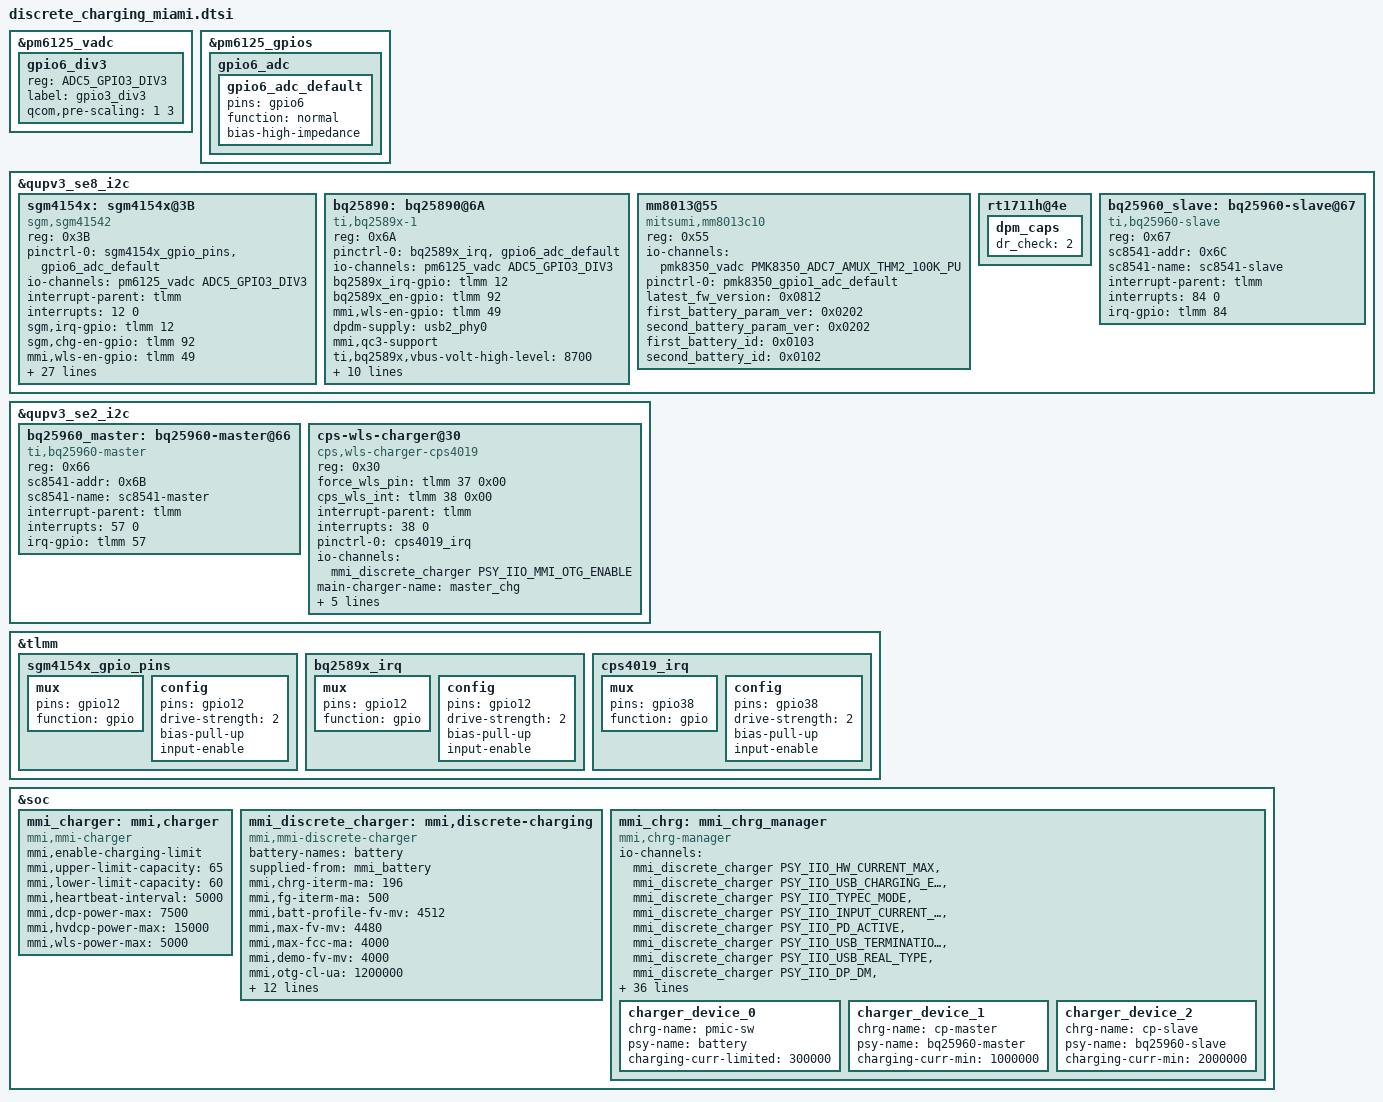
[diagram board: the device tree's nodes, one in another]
/* Copyright (c) 2021, The Linux Foundation. All rights reserved.
 *
 * This program is free software; you can redistribute it and/or modify
 * it under the terms of the GNU General Public License version 2 and
 * only version 2 as published by the Free Software Foundation.
 *
 * This program is distributed in the hope that it will be useful,
 * but WITHOUT ANY WARRANTY; without even the implied warranty of
 * MERCHANTABILITY or FITNESS FOR A PARTICULAR PURPOSE.  See the
 * GNU General Public License for more details.
 */

#include <dt-bindings/iio/qti_power_supply_iio.h>

&pm6125_vadc {
	gpio6_div3{
		reg = <ADC5_GPIO3_DIV3>;
		label = "gpio3_div3";
		qcom,pre-scaling = <1 3>;
	};
};

&pm6125_gpios {
	gpio6_adc{
		gpio6_adc_default:gpio6_adc_default{
			pins = "gpio6";
			function = "normal";
			bias-high-impedance;
		};
	};
};

&qupv3_se8_i2c {
	status = "okay";

	sgm4154x: sgm4154x@3B {
		status = "okay";
		compatible = "sgm,sgm41542";
		reg = <0x3B>;

		pinctrl-names = "default";
		pinctrl-0 = <&sgm4154x_gpio_pins &gpio6_adc_default>;
		#io-channel-cells = <1>;
		io-channels = <&pm6125_vadc ADC5_GPIO3_DIV3>;
		io-channel-names = "gpio3_div3";

		interrupt-parent = <&tlmm>;
		interrupts = <12 0>;            //irq num base on hardware design
		sgm,irq-gpio = <&tlmm 12 0>;     //irq num base on hardware design
		sgm,chg-en-gpio = <&tlmm 92 0>;   //gpio num base on hardware design  1.MTK parent node name is pio  2.QUALCOMM parent node name is tlmm or other
		mmi,wls-en-gpio = <&tlmm 49 0>;

		dpdm-supply = <&usb2_phy0>;
		mmi,qc3-support;
		mmi,wls-max-icl = <1000000>;
		input-voltage-limit-microvolt = <4700000>;

		/* sw jeita  parameter customer defined*/
		enable_sw_jeita;
		jeita_temp_above_t4_cv = <0>;
		jeita_temp_t3_to_t4_cv = <4100000>;
		jeita_temp_t2_to_t3_cv = <4350000>;
		jeita_temp_t1_to_t2_cv = <4350000>;
		jeita_temp_t0_to_t1_cv = <0>;
		jeita_temp_below_t0_cv = <0>;

		jeita_temp_above_t4_cc_current = <0>;
		jeita_temp_t3_to_t4_cc_current = <1000000>;
		jeita_temp_t2_to_t3_cc_current = <1250000>;
		jeita_temp_t1_to_t2_cc_current = <1000000>;
		jeita_temp_below_t0_cc_current = <0>;

		temp_t4_thres = <50>;
		temp_t4_thres_minus_x_degree = <48>;
		temp_t3_thres = <45>;
		temp_t3_thres_minus_x_degree = <45>;
		temp_t2_thres = <20>;
		temp_t2_thres_plus_x_degree = <15>;
		temp_t1_thres = <0>;
		temp_t1_thres_plus_x_degree = <0>;
		temp_t0_thres = <0>;
		temp_t0_thres_plus_x_degree = <2>;
		temp_neg_10_thres = <0>;
	};

	bq25890: bq25890@6A {
		status = "okay";
		compatible = "ti,bq2589x-1";
		reg = <0x6A>;

		pinctrl-names = "default";
		pinctrl-0 = <&bq2589x_irq &gpio6_adc_default>;
		#io-channel-cells = <1>;
		io-channels = <&pm6125_vadc ADC5_GPIO3_DIV3>;
		io-channel-names = "gpio3_div3";

		bq2589x_irq-gpio = <&tlmm 12 0>;
		bq2589x_en-gpio = <&tlmm 92 0>;
		mmi,wls-en-gpio = <&tlmm 49 0>;
		dpdm-supply = <&usb2_phy0>;

		mmi,qc3-support;
		ti,bq2589x,vbus-volt-high-level = <8700>;/* tune adapter to output 9v */
		ti,bq2589x,vbus-volt-low-level = <4400>;/* tune adapter to output 5v */
		ti,bq2589x,vbat-min-volt-to-tuneup = <3000>;
		ti,bq2589x,charge-voltage = <4450>;
		ti,bq2589x,charge-current = <3000>;
		ti,bq2589x,term-current = <128>;
		ti,bq2589x,enable-auto-dpdm;
		ti,bq2589x,enable-termination;
		ti,bq2589x,enable-ico;
		ti,bq2589x,use-absolute-vindpm;
		ti,bq2589x,vindpm = <4700>;
	};

	mm8013@55 {
		compatible = "mitsumi,mm8013c10";
		reg = <0x55>;
		status = "okay";
		io-channels = <&pmk8350_vadc PMK8350_ADC7_AMUX_THM2_100K_PU>;
		io-channel-names = "batt_therm";

		pinctrl-names = "default";
		pinctrl-0 = <&pmk8350_gpio1_adc_default>;

		latest_fw_version = <0x0812>;
		first_battery_param_ver = <0x0202>;
		second_battery_param_ver = <0x0202>;

		first_battery_id = <0x0103>;
		second_battery_id = <0x0102>;
	};

	rt1711h@4e {
		dpm_caps {
			/* 0: disable, 1: prefer_ufp, 2: prefer_dfp */
			dr_check = <2>;
		};
	};

};

&qupv3_se2_i2c {
	status = "okay";
	bq25960_master:bq25960-master@66 {
		status = "okay";
		compatible = "ti,bq25960-master";
		reg = <0x66>;
		sc8541-addr = <0x6B>;
		sc8541-name = "sc8541-master";
		#io-channel-cells = <1>;
		interrupt-parent = <&tlmm>;
		interrupts = <57 0>;
		irq-gpio = <&tlmm 57 0>;
	};

};

&qupv3_se8_i2c {
	status = "okay";
	bq25960_slave:bq25960-slave@67 {
		status = "okay";
		compatible = "ti,bq25960-slave";
		reg = <0x67>;
		sc8541-addr = <0x6C>;
		sc8541-name = "sc8541-slave";
		#io-channel-cells = <1>;
		interrupt-parent = <&tlmm>;
		interrupts = <84 0>;
		irq-gpio = <&tlmm 84 0>;
	};

};

&qupv3_se2_i2c {
	status = "okay";
	cps-wls-charger@30 {
		status = "okay";
		compatible = "cps,wls-charger-cps4019";
		reg = <0x30>;
		force_wls_pin = <&tlmm 37 0x00>;
		cps_wls_int = <&tlmm 38 0x00>;
		interrupt-parent = <&tlmm>;
		interrupts = <38 0>;
		interrupt-names = "cps_wls_int";

		pinctrl-names = "default";
		pinctrl-0 = <&cps4019_irq>;

		io-channels = <&mmi_discrete_charger PSY_IIO_MMI_OTG_ENABLE>;
		io-channel-names = "otg_enable";

		main-charger-name = "master_chg";
		supplied-from = "battery";

		wireless-fw-name = "cps4019.hex";
		fw_ver_major = <0>;
		fw_ver_minor = <0xE>;

		use_bl_in_h;
	};
};

&tlmm {
	sgm4154x_gpio_pins: sgm4154x_gpio_pins {
		mux {
			pins = "gpio12";
			function = "gpio";
		};

		config {
			pins = "gpio12";
			drive-strength = <2>;
			bias-pull-up;
			input-enable;
		};
	};
	bq2589x_irq: bq2589x_irq {
		mux {
			pins = "gpio12";
			function = "gpio";
		};

		config {
			pins = "gpio12";
			drive-strength = <2>;
			bias-pull-up;
			input-enable;
		};
	};

	cps4019_irq: cps4019_irq {
		mux {
			pins = "gpio38";
			function = "gpio";
		};

		config {
			pins = "gpio38";
			drive-strength = <2>;
			bias-pull-up;
			input-enable;
		};
	};
};

&soc {
	mmi_charger: mmi,charger {
		status = "ok";
		compatible = "mmi,mmi-charger";
		mmi,enable-charging-limit;
		mmi,upper-limit-capacity = <65>;
		mmi,lower-limit-capacity = <60>;
		mmi,heartbeat-interval = <5000>;
		mmi,dcp-power-max = <7500>;
		mmi,hvdcp-power-max = <15000>;
		mmi,wls-power-max = <5000>;
	};

	mmi_discrete_charger: mmi,discrete-charging {
		status = "ok";
		compatible = "mmi,mmi-discrete-charger";
		#io-channel-cells = <1>;
		battery-names = "battery";
		supplied-from = "mmi_battery";

		mmi,chrg-iterm-ma = <196>;
		mmi,fg-iterm-ma = <500>;
		mmi,batt-profile-fv-mv = <4512>;
		mmi,max-fv-mv = <4480>;
		mmi,max-fcc-ma = <4000>;
		mmi,demo-fv-mv = <4000>;
		mmi,otg-cl-ua = <1200000>;
		mmi,wls-max-icl-ua = <1000000>;
		mmi,df-serialnum = "SB18D50729";
		mmi,mmi-temp-zones = <0 4200 800 0>,
				<10 4250 2000 1000>,
				<15 0 2000 2000>,
				<45 0 4000 4000>,
				<60 4200 4000 0>;
		mmi,mmi-ffc-zones =
				<15 4480 196 500>,
				<25 4512 590 500>,
				<35 4512 712 500>,
				<45 4512 804 500>,
				<60 4480 196 500>;
		mmi,thermal-mitigation = <4000000 3000000 2500000
				2000000 1500000
				1200000 900000
				600000 300000>;
		mmi,usb-pd-supported;
		mmi,cfg-chgmod-to-fg;
	};

	mmi_chrg: mmi_chrg_manager {
		compatible = "mmi,chrg-manager";
		#io-channel-cells = <1>;
		io-channels = <&mmi_discrete_charger PSY_IIO_HW_CURRENT_MAX>,
				<&mmi_discrete_charger PSY_IIO_USB_CHARGING_ENABLED>,
				<&mmi_discrete_charger PSY_IIO_TYPEC_MODE>,
				<&mmi_discrete_charger PSY_IIO_INPUT_CURRENT_SETTLED>,
				<&mmi_discrete_charger PSY_IIO_PD_ACTIVE>,
				<&mmi_discrete_charger PSY_IIO_USB_TERMINATION_ENABLED>,
				<&mmi_discrete_charger PSY_IIO_USB_REAL_TYPE>,
				<&mmi_discrete_charger PSY_IIO_DP_DM>,
				<&mmi_discrete_charger PSY_IIO_MMI_QC3P_POWER>,
				<&mmi_discrete_charger PSY_IIO_CP_ENABLE>,
				<&bq25960_master PSY_IIO_CP_ENABLE>,
				<&bq25960_master PSY_IIO_MMI_CP_INPUT_CURRENT_NOW>,
				<&bq25960_master PSY_IIO_MMI_CP_INPUT_VOLTAGE_NOW>,
				<&bq25960_master PSY_IIO_CP_STATUS1>,
				<&bq25960_master PSY_IIO_CP_CLEAR_ERROR>,
				<&bq25960_slave PSY_IIO_CP_ENABLE>,
				<&bq25960_slave PSY_IIO_MMI_CP_INPUT_CURRENT_NOW>,
				<&bq25960_slave PSY_IIO_MMI_CP_INPUT_VOLTAGE_NOW>,
				<&bq25960_slave PSY_IIO_CP_STATUS1>,
				<&bq25960_slave PSY_IIO_CP_CLEAR_ERROR>;

		io-channel-names = "hw_current_max",
					"charging_enabled",
					"typec_mode",
					"input_current_settled",
					"pd_active",
					"termination_enabled",
					"usb_real_type",
					"battery_dp_dm",
					"usb_qc3p_power",
					"mmi_cp_enabled_status",
					"cp_enabled",
					"cp_input_current_now",
					"cp_input_voltage_settled",
					"cp_status1",
					"cp_clear_error",
					"cp_slave_enabled",
					"cp_slave_input_current_now",
					"cp_slave_input_voltage_settled",
					"cp_slave_status1",
					"cp_slave_clear_error";

	//	qcom,usbpd-phandle = <&pm7250b_pdphy>;
		mmi,pps-volt-steps = <20000>;
		mmi,pps-curr-steps = <100000>;
		mmi,pd-volt-max = <11000000>;
		mmi,pd-curr-max = <5900000>;
		mmi,batt-curr-boost = <300000>;
		mmi,batt-ovp-lmt = <4550000>;
		mmi,typec-middle-current = <2000000>;
		mmi,pd-allow-min-current = <1000000>;
		mmi,step-first-current-comp = <0>;
		mmi,dont-rerun-aicl;
		mmi,qc3p-max-ibus-ma = <3000>;
		mmi,qc3p-volt-steps = <20000>;
		mmi,qc3p-volt-max = <10000000>;
		mmi,chrg-temp-zones-num = <5>;
		mmi,mmi-chrg-temp-zones =
					<0 4200 800 0 0 0 0 0 0>,
					<10 4250 2000 4480 1000 0 0 0 0>,
					<15 4480 2000 0 0 0 0 0 0>,
					<45 4250 12200 4300 8000 4480 6000 4510 4000>,
					<60 4200 4000 0 0 0 0 0 0>;
		mmi,thermal-mitigation =
					<12200000>,
					<11000000>,
					<10000000>,
					<9000000>,
					<8000000>,
					<7000000>,
					<6000000>,
					<5000000>,
					<4000000>,
					<3000000>,
					<2000000>,
					<1000000>;
		charger_device_0 {
			chrg-name = "pmic-sw";
			psy-name = "battery";
			charging-curr-limited = <300000>;
		};
		charger_device_1 {
			chrg-name = "cp-master";
			psy-name = "bq25960-master";
			charging-curr-min = <1000000>;
		};
		charger_device_2 {
			chrg-name = "cp-slave";
			psy-name = "bq25960-slave";
			charging-curr-min = <2000000>;
		};
	};
};

